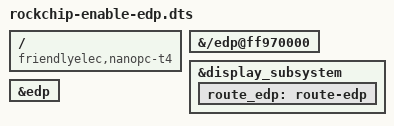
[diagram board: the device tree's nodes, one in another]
/dts-v1/;
/plugin/;

/ {
	compatible = "friendlyelec,nanopc-t4", "rockchip,rk3399";

	fragment@0 {
		target-path = "/edp@ff970000";

		__overlay__ {
			status = "okay";
		};
	};

	fragment@1 {
		target = <&display_subsystem>;

		__overlay__ {
			route_edp: route-edp {
				status = "okay";
			};
		};
	};

	fragment@2 {
		target = <&edp>;

		__overlay__ {
			status = "okay";
		};
	};

};
